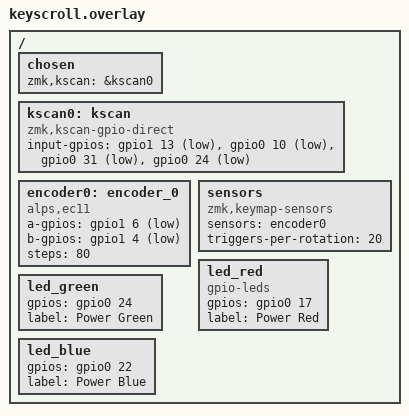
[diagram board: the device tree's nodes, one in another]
#include <dt-bindings/zmk/keys.h>

// ────────────────────────────────────────
// Choose your board reference: use pro_micro labels (Arduino-style, common for nice!nano clones)
// Adjust these pins to match your actual wiring!
// Example assumes:
// - Button 1 on D5 (often P0.06 or similar)
// - Button 2 on D6
// - Encoder A on D7, B on D8
// Check your board's pinout diagram (search "nice_nano pinout" or your clone's markings)
// ────────────────────────────────────────

/ {
    chosen {
        zmk,kscan = &kscan0;
    };

    // Direct GPIO for keys (buttons report as pressed when pulled low)
    kscan0: kscan {
        compatible = "zmk,kscan-gpio-direct";

        input-gpios
            = <&gpio1 13 (GPIO_ACTIVE_LOW | GPIO_PULL_UP)>   // Undo 
            , <&gpio0 10 (GPIO_ACTIVE_LOW | GPIO_PULL_UP)>   // Grid
            , <&gpio0 31 (GPIO_ACTIVE_LOW | GPIO_PULL_UP)>   // BT Clear
	    , <&gpio0 24 (GPIO_ACTIVE_LOW | GPIO_PULL_UP)>  // RGB power button switch
            ;
    };

    // Rotary Encoder (EC11 on top)
    encoder0: encoder_0 {
        compatible = "alps,ec11";
        a-gpios = <&gpio1 6 (GPIO_ACTIVE_LOW | GPIO_PULL_UP)>;   // Encoder pin A
        b-gpios = <&gpio1 4 (GPIO_ACTIVE_LOW | GPIO_PULL_UP)>;   // Encoder pin B
	steps = <80>;
	status = "okay";
    };
    sensors: sensors {
	compatible = "zmk,keymap-sensors";
	sensors = <&encoder0>;
	triggers-per-rotation = <20>;
    };

    led_red: led_red {
        compatible = "gpio-leds";
        gpios = <&gpio0 17 GPIO_ACTIVE_HIGH>;
        label = "Power Red";
    };

    led_green: led_green {
	gpios = <&gpio0 24 GPIO_ACTIVE_HIGH>;
        label = "Power Green";
    };

    led_blue: led_blue {
	gpios = <&gpio0 22 GPIO_ACTIVE_HIGH>;
	label = "Power Blue";
    };
};
